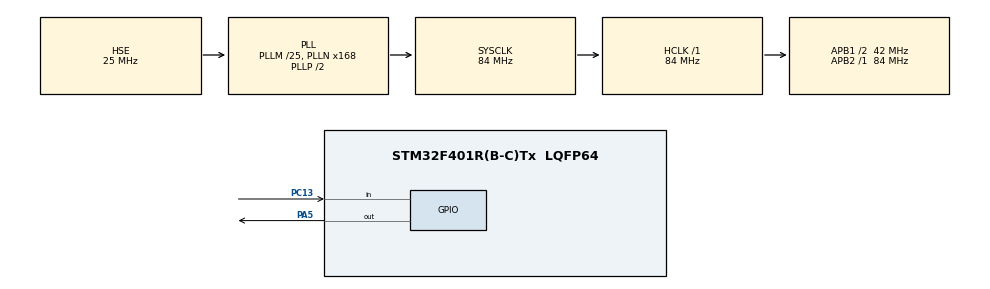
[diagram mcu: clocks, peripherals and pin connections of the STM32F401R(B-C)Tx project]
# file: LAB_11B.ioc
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Mcu.Family=STM32F4
Mcu.Name=STM32F401R(B-C)Tx
Mcu.Package=LQFP64
NVIC.PriorityGroup=NVIC_PRIORITYGROUP_4
PA13.Mode=Serial_Wire
PA13.Signal=SYS_JTMS-SWDIO
PA14.Mode=Serial_Wire
PA14.Signal=SYS_JTCK-SWCLK
PA5.Signal=GPIO_Output
PC13-ANTI_TAMP.Signal=GPIO_Input
PH0\ -\ OSC_IN.Mode=HSE-External-Clock-Source
PH0\ -\ OSC_IN.Signal=RCC_OSC_IN
PH1\ -\ OSC_OUT.Mode=HSE-External-Clock-Source
PH1\ -\ OSC_OUT.Signal=RCC_OSC_OUT
ProjectManager.HeapSize=0x200
ProjectManager.StackSize=0x400
ProjectManager.TargetToolchain=MDK-ARM V5.32
RCC.48MHZClocksFreq_Value=42000000
RCC.AHBFreq_Value=84000000
RCC.APB1CLKDivider=RCC_HCLK_DIV2
RCC.APB1Freq_Value=42000000
RCC.APB1TimFreq_Value=84000000
RCC.APB2Freq_Value=84000000
RCC.APB2TimFreq_Value=84000000
RCC.CortexFreq_Value=84000000
RCC.HCLKFreq_Value=84000000
RCC.HSE_VALUE=25000000
RCC.HSI_VALUE=16000000
RCC.LSE_VALUE=32768
RCC.PLLM=25
RCC.PLLN=168
RCC.PLLSourceVirtual=RCC_PLLSOURCE_HSE
RCC.SYSCLKFreq_VALUE=84000000
RCC.SYSCLKSource=RCC_SYSCLKSOURCE_PLLCLK
RCC.VCOOutputFreq_Value=168000000
board=custom

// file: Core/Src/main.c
/* USER CODE BEGIN Header */
/**
  ******************************************************************************
  * @file           : main.c
  * @brief          : Main program body
  *
  *                   FPIoT Lab Evaluation CAT-11 - Task 2
  *                   On-board Switch Control with State Remembrance
  *
  *                   Each valid press of the user button B1 (PC13) toggles the
  *                   on-board LED LD2 (PA5). The LED keeps (remembers) its
  *                   state after the button is released, because the press is
  *                   handled as a single edge event instead of a level.
  ******************************************************************************
  * @attention
  *
  * Copyright (c) 2026 STMicroelectronics.
  * All rights reserved.
  *
  * This software is licensed under terms that can be found in the LICENSE file
  * in the root directory of this software component.
  * If no LICENSE file comes with this software, it is provided AS-IS.
  *
  ******************************************************************************
  */
/* USER CODE END Header */
#include "main.h"

/* USER CODE BEGIN PD */

/* On-board user LED LD2 of the NUCLEO-F401RE : PA5, active HIGH */
#define LED_PORT              GPIOA
#define LED_PIN               GPIO_PIN_5
#define LED_ON_LEVEL          GPIO_PIN_SET
#define LED_OFF_LEVEL         GPIO_PIN_RESET

/* On-board user button B1 of the NUCLEO-F401RE : PC13, active LOW
   (the board provides the pull-up, so the pin reads LOW while pressed) */
#define BUTTON_PORT           GPIOC
#define BUTTON_PIN            GPIO_PIN_13
#define BUTTON_PRESSED_LEVEL  GPIO_PIN_RESET

/* Software debounce window for the mechanical button */
#define DEBOUNCE_MS           30u

/* USER CODE END PD */

/* USER CODE BEGIN PV */
/* Debounce state machine */
static uint8_t  button_raw_last     = 0u;  /* last raw level read from PC13     */
static uint8_t  button_stable       = 0u;  /* debounced (accepted) state        */
static uint32_t button_change_tick  = 0u;  /* tick of the last raw level change */

/* Remembered output state : survives the button release */
static uint8_t  led_state = 0u;
/* USER CODE END PV */

void SystemClock_Config(void);
static void MX_GPIO_Init(void);
/* USER CODE BEGIN PFP */
static void Led_Write(uint8_t on);
static void Led_Toggle(void);
static uint8_t Button_IsPressed(void);
static uint8_t Button_ScanPressEvent(void);
/* USER CODE END PFP */

/* USER CODE BEGIN 0 */

/**
  * @brief  Drives the on-board user LED to the requested logical state.
  * @param  on 0 = LED off, any other value = LED on
  * @retval None
  */
static void Led_Write(uint8_t on)
{
  led_state = (on != 0u) ? 1u : 0u;
  HAL_GPIO_WritePin(LED_PORT, LED_PIN, (led_state != 0u) ? LED_ON_LEVEL : LED_OFF_LEVEL);
}

/**
  * @brief  Inverts the on-board user LED state.
  * @retval None
  */
static void Led_Toggle(void)
{
  led_state = (led_state != 0u) ? 0u : 1u;
  HAL_GPIO_TogglePin(LED_PORT, LED_PIN);
}

/**
  * @brief  Reads the user button and converts it to a logical "pressed" flag.
  * @retval 1 when the button is pressed, 0 otherwise
  */
static uint8_t Button_IsPressed(void)
{
  return (HAL_GPIO_ReadPin(BUTTON_PORT, BUTTON_PIN) == BUTTON_PRESSED_LEVEL) ? 1u : 0u;
}

/**
  * @brief  Non-blocking debounce plus edge detection.
  *         A new level is accepted only after it stayed stable for DEBOUNCE_MS,
  *         and a press event is reported once per press (not once per loop
  *         iteration and not repeatedly while the button is held).
  * @retval 1 on the confirmed press edge, 0 otherwise
  */
static uint8_t Button_ScanPressEvent(void)
{
  uint32_t now = HAL_GetTick();
  uint8_t  raw = Button_IsPressed();

  /* Remember when the raw level last changed */
  if (raw != button_raw_last)
  {
    button_raw_last    = raw;
    button_change_tick = now;
  }

  /* Accept the new level only once it has been stable long enough */
  if (((uint32_t)(now - button_change_tick) >= DEBOUNCE_MS) && (button_raw_last != button_stable))
  {
    button_stable = button_raw_last;

    if (button_stable != 0u) /* released -> pressed : one valid press */
    {
      return 1u;
    }
  }

  return 0u;
}

/* USER CODE END 0 */

int main(void)
{

  /* MCU Configuration--------------------------------------------------------*/

  /* Reset of all peripherals, Initializes the Flash interface and the Systick. */
  HAL_Init();

  /* Configure the system clock */
  SystemClock_Config();

  /* Initialize all configured peripherals */
  MX_GPIO_Init();
  /* USER CODE BEGIN 2 */

  /* Seed the debounce state machine with the current button level so that a
     button already held at reset does not generate a false press */
  button_stable      = Button_IsPressed();
  button_raw_last    = button_stable;
  button_change_tick = HAL_GetTick();

  /* LED starts from a known state and remembers it */
  Led_Write(0);

  /* USER CODE END 2 */

  /* Infinite loop */
  while (1)
  {

    /* USER CODE BEGIN 3 */

    /* Task 2 : state remembrance.
       The LED is toggled only when a valid press edge is detected and it keeps
       that state after the button is released, because the output is driven
       from the remembered variable led_state and not from the button level. */
    if (Button_ScanPressEvent() != 0u)
    {
      Led_Toggle();
    }
  }
  /* USER CODE END 3 */
}

void SystemClock_Config(void)
{
  RCC_OscInitTypeDef RCC_OscInitStruct = {0};
  RCC_ClkInitTypeDef RCC_ClkInitStruct = {0};

  /** Configure the main internal regulator output voltage
  */
  __HAL_RCC_PWR_CLK_ENABLE();
  __HAL_PWR_VOLTAGESCALING_CONFIG(PWR_REGULATOR_VOLTAGE_SCALE2);

  /** Initializes the RCC Oscillators according to the specified parameters
  * in the RCC_OscInitTypeDef structure.
  */
  RCC_OscInitStruct.OscillatorType = RCC_OSCILLATORTYPE_HSE;
  RCC_OscInitStruct.HSEState = RCC_HSE_BYPASS;
  RCC_OscInitStruct.PLL.PLLState = RCC_PLL_ON;
  RCC_OscInitStruct.PLL.PLLSource = RCC_PLLSOURCE_HSE;
  RCC_OscInitStruct.PLL.PLLM = 25;
  RCC_OscInitStruct.PLL.PLLN = 168;
  RCC_OscInitStruct.PLL.PLLP = RCC_PLLP_DIV2;
  RCC_OscInitStruct.PLL.PLLQ = 4;
  if (HAL_RCC_OscConfig(&RCC_OscInitStruct) != HAL_OK)
  {
    Error_Handler();
  }

  /** Initializes the CPU, AHB and APB buses clocks
  */
  RCC_ClkInitStruct.ClockType = RCC_CLOCKTYPE_HCLK|RCC_CLOCKTYPE_SYSCLK
                              |RCC_CLOCKTYPE_PCLK1|RCC_CLOCKTYPE_PCLK2;
  RCC_ClkInitStruct.SYSCLKSource = RCC_SYSCLKSOURCE_PLLCLK;
  RCC_ClkInitStruct.AHBCLKDivider = RCC_SYSCLK_DIV1;
  RCC_ClkInitStruct.APB1CLKDivider = RCC_HCLK_DIV2;
  RCC_ClkInitStruct.APB2CLKDivider = RCC_HCLK_DIV1;

  if (HAL_RCC_ClockConfig(&RCC_ClkInitStruct, FLASH_LATENCY_2) != HAL_OK)
  {
    Error_Handler();
  }
}

static void MX_GPIO_Init(void)
{
  GPIO_InitTypeDef GPIO_InitStruct = {0};

  /* GPIO Ports Clock Enable */
  __HAL_RCC_GPIOC_CLK_ENABLE();
  __HAL_RCC_GPIOH_CLK_ENABLE();
  __HAL_RCC_GPIOA_CLK_ENABLE();

  /*Configure GPIO pin Output Level */
  HAL_GPIO_WritePin(GPIOA, GPIO_PIN_5, GPIO_PIN_RESET);

  /*Configure GPIO pin : PC13 */
  GPIO_InitStruct.Pin = GPIO_PIN_13;
  GPIO_InitStruct.Mode = GPIO_MODE_INPUT;
  GPIO_InitStruct.Pull = GPIO_NOPULL;
  HAL_GPIO_Init(GPIOC, &GPIO_InitStruct);

  /*Configure GPIO pin : PA5 */
  GPIO_InitStruct.Pin = GPIO_PIN_5;
  GPIO_InitStruct.Mode = GPIO_MODE_OUTPUT_PP;
  GPIO_InitStruct.Pull = GPIO_NOPULL;
  GPIO_InitStruct.Speed = GPIO_SPEED_FREQ_LOW;
  HAL_GPIO_Init(GPIOA, &GPIO_InitStruct);

}

void Error_Handler(void)
{
  __disable_irq();
  while (1)
  {
  }
}
